# STM32N645xx register map
File version: 1.0
Registers are 32-bit, read-write, reset 0x0 unless marked. A register's access mark holds for its fields unless they carry their own. Offsets are from the block's base; [hi:lo] are bit positions; 'fields as' and 'values as' point back to an identical list.

## FMC_Bank1_R — Flexible Memory Controller Bank1
Base 0x48024000
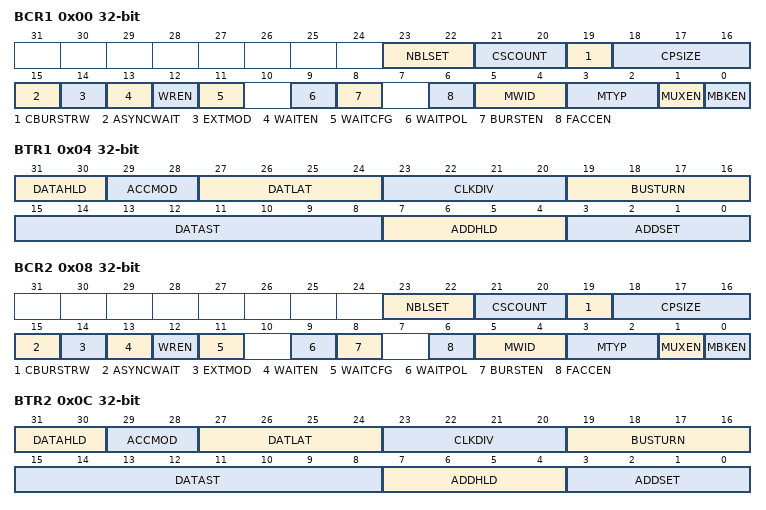
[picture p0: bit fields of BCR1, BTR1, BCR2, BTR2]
0x00 BCR1 — NOR/PSRAM chip-select control register(BCR) and chip-select timing register(BTR)
  [23:22] NBLSET — Byte lane (NBL) setup
  [21:20] CSCOUNT — Chip Select (CS) counter
  [19] CBURSTRW — Write burst enable
  [18:16] CPSIZE — CRAM page size
  [15] ASYNCWAIT — Wait signal during asynchronous transfers
  [14] EXTMOD — Extended mode enable
  [13] WAITEN — Wait enable bit
  [12] WREN — Write enable bit
  [11] WAITCFG — Wait timing configuration
  [9] WAITPOL — Wait signal polarity bit
  [8] BURSTEN — Burst enable bit
  [6] FACCEN — Flash access enable
  [5:4] MWID — Memory data bus width
  [3:2] MTYP — Memory type
  [1] MUXEN — Address/data multiplexing enable bit
  [0] MBKEN — Memory bank enable bit
0x04 BTR1 — NOR/PSRAM chip-select control register(BCR) and chip-select timing register(BTR)
  [31:30] DATAHLD — Data Hold phase duration
  [29:28] ACCMOD — Access mode
  [27:24] DATLAT — Data latency for synchronous memory
  [23:20] CLKDIV — Clock divide ratio
  [19:16] BUSTURN — Bus turnaround phase duration
  [15:8] DATAST — Data-phase duration
  [7:4] ADDHLD — Address-hold phase duration
  [3:0] ADDSET — Address setup phase duration
0x08 BCR2 — NOR/PSRAM chip-select control register(BCR) and chip-select timing register(BTR)
  fields as BCR1
0x0C BTR2 — NOR/PSRAM chip-select control register(BCR) and chip-select timing register(BTR)
  fields as BTR1
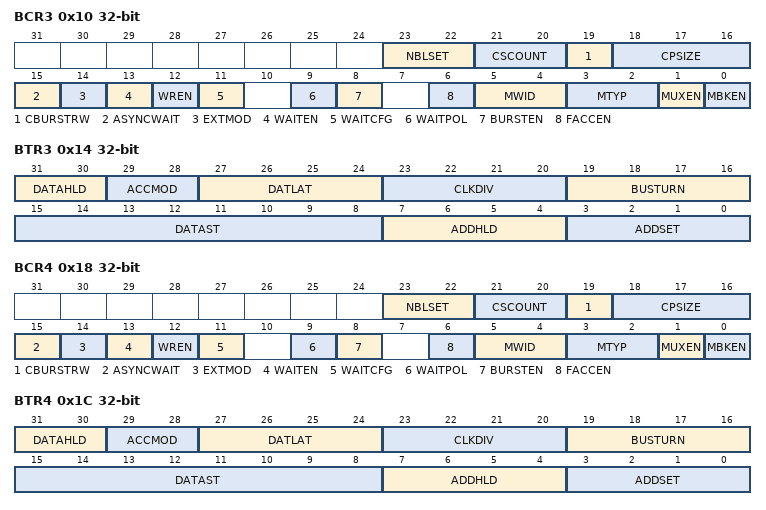
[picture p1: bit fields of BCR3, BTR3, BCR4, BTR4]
0x10 BCR3 — NOR/PSRAM chip-select control register(BCR) and chip-select timing register(BTR)
  fields as BCR1
0x14 BTR3 — NOR/PSRAM chip-select control register(BCR) and chip-select timing register(BTR)
  fields as BTR1
0x18 BCR4 — NOR/PSRAM chip-select control register(BCR) and chip-select timing register(BTR)
  fields as BCR1
0x1C BTR4 — NOR/PSRAM chip-select control register(BCR) and chip-select timing register(BTR)
  fields as BTR1

## FMC_Common_R — Flexible Memory Controller Common
Base 0x48024020
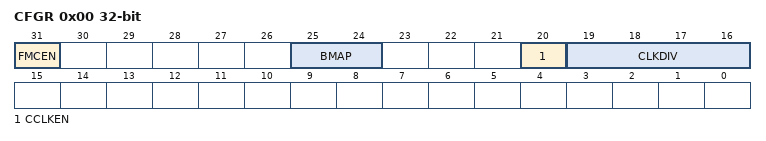
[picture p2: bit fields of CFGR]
0x00 CFGR — FMC common configuration register
  [31] FMCEN — FMC controller enable
  [25:24] BMAP — FMC memory region mapping
  [20] CCLKEN — Continuous clock enable
  [19:16] CLKDIV — Clock divide ratio (for FMC_CLK signal)

## FMC_Bank1E_R — Flexible Memory Controller Bank1E
Base 0x48024104
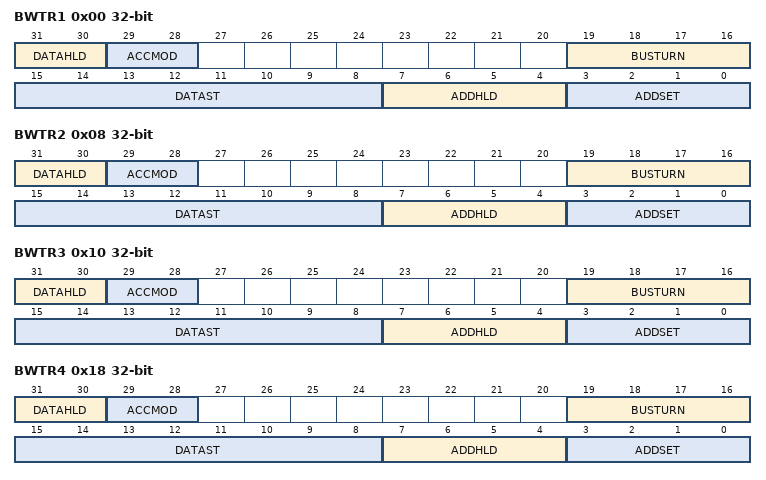
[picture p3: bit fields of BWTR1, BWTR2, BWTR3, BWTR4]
0x00 BWTR1 — NOR/PSRAM write timing registers
  [31:30] DATAHLD — Data Hold phase duration
  [29:28] ACCMOD — Access mode
  [19:16] BUSTURN — Bus turnaround phase duration
  [15:8] DATAST — Data-phase duration
  [7:4] ADDHLD — Address-hold phase duration
  [3:0] ADDSET — Address setup phase duration
0x08 BWTR2 — NOR/PSRAM write timing registers
  fields as BWTR1
0x10 BWTR3 — NOR/PSRAM write timing registers
  fields as BWTR1
0x18 BWTR4 — NOR/PSRAM write timing registers
  fields as BWTR1

## FMC_Bank5_6_R — Flexible Memory Controller Bank2
Base 0x48024140
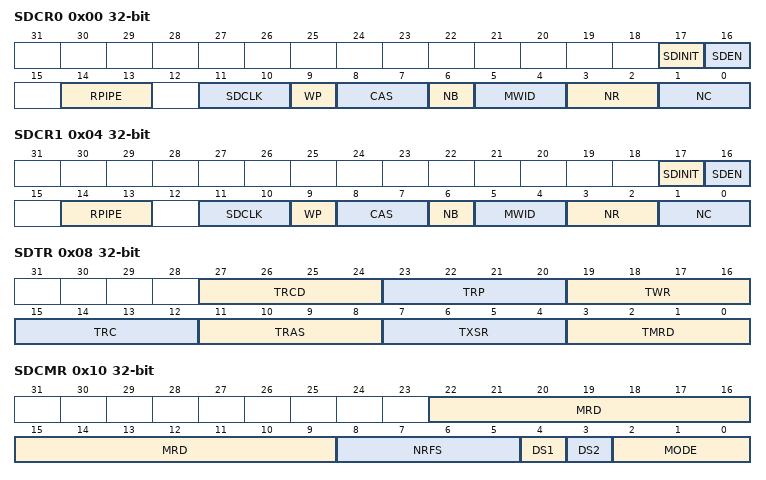
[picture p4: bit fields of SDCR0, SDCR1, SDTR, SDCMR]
0x00 SDCR0 — SDRAM device 1/2 control register
  [17] SDINIT — SDRAM device initialization
  [16] SDEN — SDRAM device enable
  [14:13] RPIPE — Read pipe
  [11:10] SDCLK — SDRAM clock configuration
  [9] WP — Write protection
  [8:7] CAS — CAS latency
  [6] NB — Number of internal banks
  [5:4] MWID — Memory data bus width
  [3:2] NR — Number of row address bits
  [1:0] NC — Number of column address bits
0x04 SDCR1 — SDRAM device 1/2 control register
  fields as SDCR0
0x08 SDTR — SDRAM timing register
  [27:24] TRCD — Row to column delay
  [23:20] TRP — Row precharge delay
  [19:16] TWR — Recovery delay
  [15:12] TRC — Row cycle delay
  [11:8] TRAS — Self refresh time
  [7:4] TXSR — Exit self-refresh delay
  [3:0] TMRD — Load mode register to active
0x10 SDCMR — SDRAM command mode register
  [22:9] MRD — Mode register definition
  [8:5] NRFS — Number of auto-refresh
  [4] DS1 — Command targeting SDRAM device 1
  [3] DS2 — Command targeting SDRAM device 2
  [2:0] MODE — Command mode
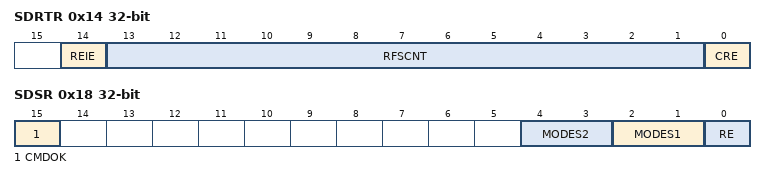
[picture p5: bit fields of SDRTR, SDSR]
0x14 SDRTR — SDRAM refresh timer register
  [14] REIE — RES interrupt enable
  [13:1] RFSCNT — Refresh timer count
  [0] CRE — Clear refresh error flag
0x18 SDSR — SDRAM status register
  [15] CMDOK — Previous command status
  [4:3] MODES2 — Status mode for bank 2
  [2:1] MODES1 — Status mode for bank 1
  [0] RE — Refresh error flag
